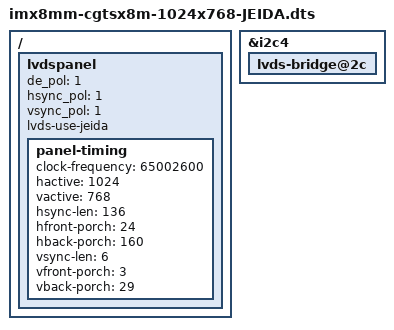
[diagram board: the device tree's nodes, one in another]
// SPDX-License-Identifier: GPL-2.0+
/*
 * Copyright 2019 NXP
 */

/dts-v1/;

#include "imx8mm-cgtsx8m.dts"

/ {
	lvdspanel {
		status = "okay";
		/delete-property/ use-uboot-settings;

		de_pol = <1>;
		hsync_pol = <1>;
		vsync_pol = <1>;
		lvds-use-jeida;

		panel-timing {
			clock-frequency = <65002600>;
			hactive = <1024>;
			vactive = <768>;
			hsync-len = <136>;
			hfront-porch = <24>;
			hback-porch = <160>;
			vsync-len = <6>;
			vfront-porch = <3>;
			vback-porch = <29>;
			};
	};
};

&i2c4 {
	lvds-bridge@2c {
		status = "okay";
	};
};
